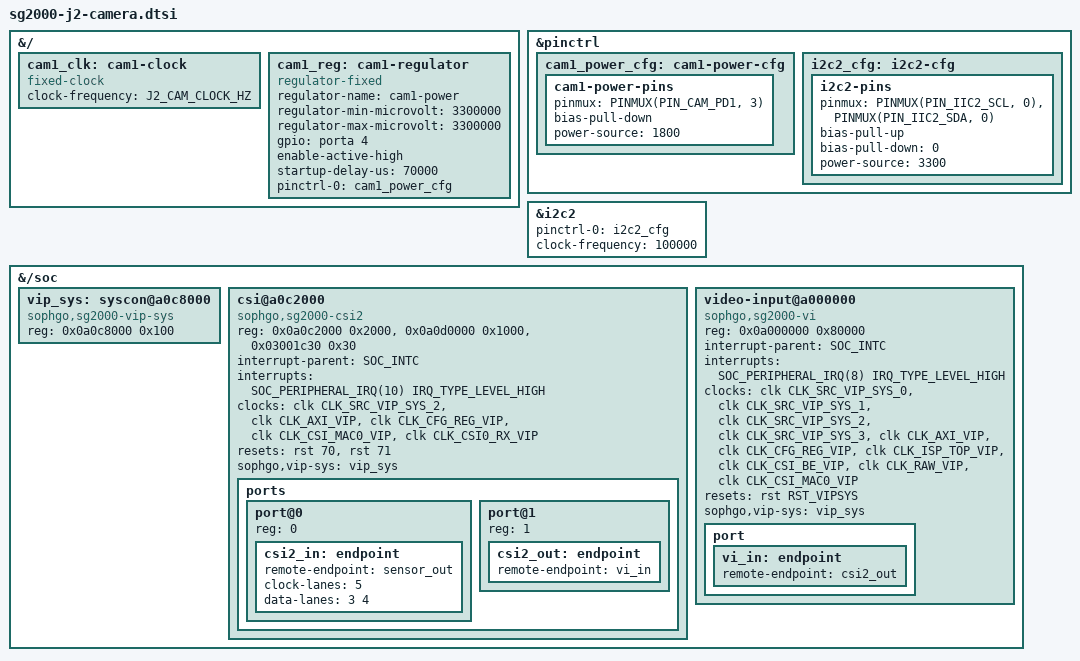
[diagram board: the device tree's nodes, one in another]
// SPDX-License-Identifier: (GPL-2.0 OR MIT)
/*
 * Shared part of the Milk-V Duo S J2 camera overlays: power, I2C, the CSI-2
 * receiver and the VI capture block. Each overlay sets J2_CAM_CLOCK_HZ to
 * its module's oscillator, includes this file and adds the sensor under
 * &i2c2 with its endpoint labelled sensor_out.
 *
 * J2 is wired like the Raspberry Pi 15-pin camera connector:
 *
 *   I2C2 (IIC2_SCL/IIC2_SDA, 3.3V)  the camera's control bus
 *   SENSOR_RSTN1 = CAM_PD1 = GPIOA4  the module's power enable (CAM_IO0);
 *                                    every rail on the module hangs off it
 *   MIPI RX lanes 3/4 data, 5 clock  CSI-2 MAC 0, port 1 of the PHY
 *
 * Raspberry Pi camera modules carry their own oscillator, so CAM_MCLK1 is
 * unused.
 */

#include <dt-bindings/clock/sophgo,cv1800.h>
#include <dt-bindings/gpio/gpio.h>
#include <dt-bindings/interrupt-controller/irq.h>
#include <dt-bindings/pinctrl/pinctrl-sg2000.h>
#include "cv18xx-reset.h"
#include "sg2000-irq.h"

&{/} {
	cam1_clk: cam1-clock {
		compatible = "fixed-clock";
		#clock-cells = <0>;
		clock-frequency = <J2_CAM_CLOCK_HZ>;
	};

	cam1_reg: cam1-regulator {
		compatible = "regulator-fixed";
		regulator-name = "cam1-power";
		regulator-min-microvolt = <3300000>;
		regulator-max-microvolt = <3300000>;
		gpio = <&porta 4 GPIO_ACTIVE_HIGH>;
		enable-active-high;
		startup-delay-us = <70000>;
		pinctrl-names = "default";
		pinctrl-0 = <&cam1_power_cfg>;
	};
};

&pinctrl {
	cam1_power_cfg: cam1-power-cfg {
		cam1-power-pins {
			/* keep the pull-down: the camera stays off until driven */
			pinmux = <PINMUX(PIN_CAM_PD1, 3)>;
			bias-pull-down;
			power-source = <1800>;
		};
	};

	i2c2_cfg: i2c2-cfg {
		i2c2-pins {
			pinmux = <PINMUX(PIN_IIC2_SCL, 0)>,
				 <PINMUX(PIN_IIC2_SDA, 0)>;
			bias-pull-up;
			/* pull-up alone leaves PD as is; pinconf-generic warns, applies both */
			bias-pull-down = <0>;
			power-source = <3300>;
		};
	};
};

&i2c2 {
	#address-cells = <1>;
	#size-cells = <0>;
	pinctrl-names = "default";
	pinctrl-0 = <&i2c2_cfg>;
	/*
	 * J2's I2C goes through a UM3204H auto-direction level shifter. On a
	 * 500 mm cable SCL's rising edge crawls up to the shifter's one-shot
	 * threshold with tens-of-MHz ringing on top and crosses it more than
	 * once, so the sensor counts extra clocks and transfers fail at random
	 * at any bus speed. Use a short (<= 150 mm) cable.
	 */
	clock-frequency = <100000>;
	status = "okay";
};

&{/soc} {
	#address-cells = <1>;
	#size-cells = <1>;

	vip_sys: syscon@a0c8000 {
		compatible = "sophgo,sg2000-vip-sys", "syscon";
		reg = <0x0a0c8000 0x100>;
	};

	csi@a0c2000 {
		compatible = "sophgo,sg2000-csi2";
		reg = <0x0a0c2000 0x2000>, <0x0a0d0000 0x1000>,
		      <0x03001c30 0x30>;
		reg-names = "mac", "phy", "pad";
		interrupt-parent = <SOC_INTC>;
		interrupts = <SOC_PERIPHERAL_IRQ(10) IRQ_TYPE_LEVEL_HIGH>;
		clocks = <&clk CLK_SRC_VIP_SYS_2>, <&clk CLK_AXI_VIP>,
			 <&clk CLK_CFG_REG_VIP>, <&clk CLK_CSI_MAC0_VIP>,
			 <&clk CLK_CSI0_RX_VIP>;
		clock-names = "sys2", "axi", "cfg", "mac", "rx";
		resets = <&rst 70>, <&rst 71>;
		reset-names = "phy", "phy-apb";
		sophgo,vip-sys = <&vip_sys>;

		ports {
			#address-cells = <1>;
			#size-cells = <0>;

			port@0 {
				reg = <0>;
				csi2_in: endpoint {
					remote-endpoint = <&sensor_out>;
					clock-lanes = <5>;
					data-lanes = <3 4>;
				};
			};

			port@1 {
				reg = <1>;
				csi2_out: endpoint {
					remote-endpoint = <&vi_in>;
				};
			};
		};
	};

	video-input@a000000 {
		compatible = "sophgo,sg2000-vi";
		reg = <0x0a000000 0x80000>;
		interrupt-parent = <SOC_INTC>;
		interrupts = <SOC_PERIPHERAL_IRQ(8) IRQ_TYPE_LEVEL_HIGH>;
		clocks = <&clk CLK_SRC_VIP_SYS_0>, <&clk CLK_SRC_VIP_SYS_1>,
			 <&clk CLK_SRC_VIP_SYS_2>, <&clk CLK_SRC_VIP_SYS_3>,
			 <&clk CLK_AXI_VIP>, <&clk CLK_CFG_REG_VIP>,
			 <&clk CLK_ISP_TOP_VIP>, <&clk CLK_CSI_BE_VIP>,
			 <&clk CLK_RAW_VIP>, <&clk CLK_CSI_MAC0_VIP>;
		clock-names = "sys0", "sys1", "sys2", "sys3", "axi", "cfg",
			      "isp_top", "csi_be", "raw", "csi_mac0";
		resets = <&rst RST_VIPSYS>;
		sophgo,vip-sys = <&vip_sys>;

		port {
			vi_in: endpoint {
				remote-endpoint = <&csi2_out>;
			};
		};
	};
};
